# ATSAMC21N17A device description
Architecture: CORTEX-M0PLUS; Family: SAMC; Series: SAMC21
Registers are 32-bit, read-write, reset 0x0 unless marked. A register's access mark holds for its fields unless they carry their own. Offsets are from the block's base; [hi:lo] are bit positions; {n}, {i} and the like mark numbered series; 'fields as' and 'values as' point back to an identical list; <NAME> marks a mode.

## SERCOM — Serial Communication Interface
Instances: SERCOM{n} {0x42000400+0x400*n} (n=0..5), SERCOM6 0x43000000, SERCOM7 0x43000400
Modes: I2CM when SERCOM.I2CM_CTRLA.MODE=5 under mask 6 (I2C Master Mode); I2CS when SERCOM.I2CS_CTRLA.MODE=4 under mask 6 (I2C Slave Mode); SPIS when SERCOM.SPIS_CTRLA.MODE=2 under mask 6 (SPI Slave Mode); SPIM when SERCOM.SPIM_CTRLA.MODE=3 under mask 6 (SPI Master Mode); USART_EXT when SERCOM.USART_CTRLA.MODE=0 under mask 6 (USART EXTERNAL CLOCK Mode); USART_INT when SERCOM.USART_CTRLA.MODE=1 under mask 6 (USART INTERNAL CLOCK Mode)
0x00 CTRLA <I2CM> — I2CM Control A
  [30] LOWTOUTEN — SCL Low Timeout Enable
  [29:28] INACTOUT — Inactive Time-Out
    0=DISABLE (Disabled); 1=55US (5-6 SCL Time-Out(50-60us)); 2=105US (10-11 SCL Time-Out(100-110us)); 3=205US (20-21 SCL Time-Out(200-210us))
  [27] SCLSM — SCL Clock Stretch Mode
  [25:24] SPEED — Transfer Speed
    0=STANDARD_AND_FAST_MODE (Standard Mode(Sm) Upto 100kHz and Fast Mode(Fm) Upto 400kHz); 1=FASTPLUS_MODE (Fast-mode Plus Upto 1MHz); 2=HIGH_SPEED_MODE (High-speed mode Upto 3.4MHz)
  [23] SEXTTOEN — Slave SCL Low Extend Timeout
  [22] MEXTTOEN — Master SCL Low Extend Timeout
  [21:20] SDAHOLD — SDA Hold Time
    0=DISABLE (Disabled); 1=75NS (50-100ns hold time); 2=450NS (300-600ns hold time); 3=600NS (400-800ns hold time)
  [16] PINOUT — Pin Usage
  [7] RUNSTDBY — Run in Standby
  [4:2] MODE — Operating Mode
    0=USART_EXT_CLK (USART with external clock); 1=USART_INT_CLK (USART with internal clock); 2=SPI_SLAVE (SPI in slave operation); 3=SPI_MASTER (SPI in master operation); 4=I2C_SLAVE (I2C slave operation); 5=I2C_MASTER (I2C master operation)
  [1] ENABLE
  [0] SWRST — Software Reset
0x04 CTRLB <I2CM> — I2CM Control B
  [18] ACKACT — Acknowledge Action
  [17:16] CMD — Command
  [9] QCEN — Quick Command Enable
  [8] SMEN — Smart Mode Enable
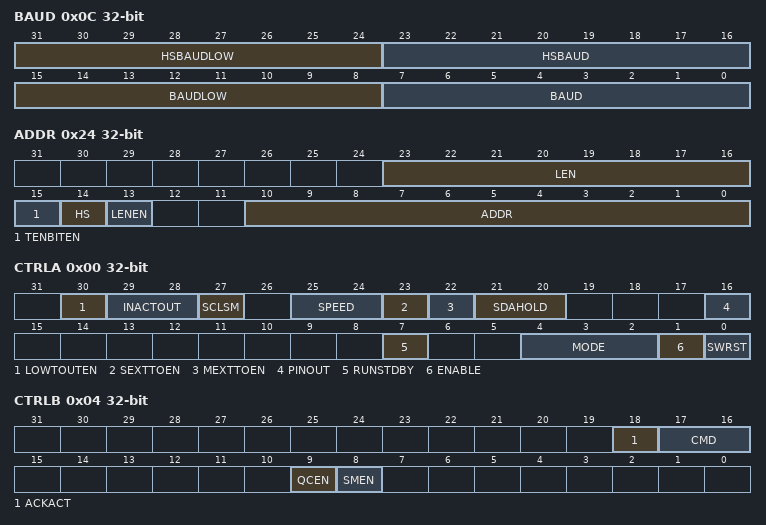
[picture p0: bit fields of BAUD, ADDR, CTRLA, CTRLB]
0x0C BAUD <I2CM> — I2CM Baud Rate
  [31:24] HSBAUDLOW — High Speed Baud Rate Value Low
  [23:16] HSBAUD — High Speed Baud Rate Value
  [15:8] BAUDLOW — Baud Rate Value Low
  [7:0] BAUD — Baud Rate Value
0x14 INTENCLR <I2CM> 8-bit (atomic clear) — I2CM Interrupt Enable Clear
  [7] ERROR — Combined Error Interrupt Disable
  [1] SB — Slave On Bus Interrupt Disable
  [0] MB — Master On Bus Interrupt Disable
0x16 INTENSET <I2CM> 8-bit (atomic set) — I2CM Interrupt Enable Set
  [7] ERROR — Combined Error Interrupt Enable
  [1] SB — Slave On Bus Interrupt Enable
  [0] MB — Master On Bus Interrupt Enable
0x18 INTFLAG <I2CM> 8-bit (atomic clear) — I2CM Interrupt Flag Status and Clear
  [7] ERROR — Combined Error Interrupt
  [1] SB — Slave On Bus Interrupt
  [0] MB — Master On Bus Interrupt
0x1A STATUS <I2CM> 16-bit — I2CM Status
  [10] LENERR — Length Error
  [9] SEXTTOUT — Slave SCL Low Extend Timeout
  [8] MEXTTOUT — Master SCL Low Extend Timeout
  [7] CLKHOLD — Clock Hold
  [6] LOWTOUT — SCL Low Timeout
  [5:4] BUSSTATE
  [2] RXNACK — Received Not Acknowledge
  [1] ARBLOST — Arbitration Lost
  [0] BUSERR — Bus Error
0x1C SYNCBUSY <I2CM> ro — I2CM Synchronization Busy
  [2] SYSOP — System Operation Synchronization Busy
  [1] ENABLE — SERCOM Enable Synchronization Busy
  [0] SWRST — Software Reset Synchronization Busy
0x24 ADDR <I2CM> — I2CM Address
  [23:16] LEN — Length
  [15] TENBITEN — Ten Bit Addressing Enable
  [14] HS — High Speed Mode
  [13] LENEN — Length Enable
  [10:0] ADDR — Address Value
0x28 DATA <I2CM> 8-bit — I2CM Data
  [7:0] DATA — Data Value
0x30 DBGCTRL <I2CM> 8-bit — I2CM Debug Control
  [0] DBGSTOP — Debug Mode
0x00 CTRLA <I2CS> — I2CS Control A
  [30] LOWTOUTEN — SCL Low Timeout Enable
  [27] SCLSM — SCL Clock Stretch Mode
  [25:24] SPEED — Transfer Speed
    values as CTRLA<I2CM>.SPEED
  [23] SEXTTOEN — Slave SCL Low Extend Timeout
  [21:20] SDAHOLD — SDA Hold Time
    values as CTRLA<I2CM>.SDAHOLD
  [16] PINOUT — Pin Usage
  [7] RUNSTDBY — Run during Standby
  [4:2] MODE — Operating Mode
    values as CTRLA<I2CM>.MODE
  [1] ENABLE
  [0] SWRST — Software Reset
0x04 CTRLB <I2CS> — I2CS Control B
  [18] ACKACT — Acknowledge Action
  [17:16] CMD — Command
  [15:14] AMODE — Address Mode
  [10] AACKEN — Automatic Address Acknowledge
  [9] GCMD — PMBus Group Command
  [8] SMEN — Smart Mode Enable
0x14 INTENCLR <I2CS> 8-bit (atomic clear) — I2CS Interrupt Enable Clear
  [7] ERROR — Combined Error Interrupt Disable
  [2] DRDY — Data Interrupt Disable
  [1] AMATCH — Address Match Interrupt Disable
  [0] PREC — Stop Received Interrupt Disable
0x16 INTENSET <I2CS> 8-bit (atomic set) — I2CS Interrupt Enable Set
  [7] ERROR — Combined Error Interrupt Enable
  [2] DRDY — Data Interrupt Enable
  [1] AMATCH — Address Match Interrupt Enable
  [0] PREC — Stop Received Interrupt Enable
0x18 INTFLAG <I2CS> 8-bit (atomic clear) — I2CS Interrupt Flag Status and Clear
  [7] ERROR — Combined Error Interrupt
  [2] DRDY — Data Interrupt
  [1] AMATCH — Address Match Interrupt
  [0] PREC — Stop Received Interrupt
0x1A STATUS <I2CS> 16-bit — I2CS Status
  [10] HS — High Speed
  [9] SEXTTOUT — Slave SCL Low Extend Timeout
  [7] CLKHOLD — Clock Hold
  [6] LOWTOUT — SCL Low Timeout
  [4] SR — Repeated Start
  [3] DIR — Read/Write Direction
  [2] RXNACK — Received Not Acknowledge
  [1] COLL — Transmit Collision
  [0] BUSERR — Bus Error
0x1C SYNCBUSY <I2CS> ro — I2CS Synchronization Busy
  [1] ENABLE — SERCOM Enable Synchronization Busy
  [0] SWRST — Software Reset Synchronization Busy
0x24 ADDR <I2CS> — I2CS Address
  [26:17] ADDRMASK — Address Mask
  [15] TENBITEN — Ten Bit Addressing Enable
  [10:1] ADDR — Address Value
  [0] GENCEN — General Call Address Enable
0x28 DATA <I2CS> 8-bit — I2CS Data
  [7:0] DATA — Data Value
0x00 CTRLA <SPIM> — SPIM Control A
  [30] DORD — Data Order
    0=MSB (MSB is transferred first); 1=LSB (LSB is transferred first)
  [29] CPOL — Clock Polarity
    0=IDLE_LOW (SCK is low when idle); 1=IDLE_HIGH (SCK is high when idle)
  [28] CPHA — Clock Phase
    0=LEADING_EDGE (The data is sampled on a leading SCK edge and changed on a trailing SCK edge); 1=TRAILING_EDGE (The data is sampled on a trailing SCK edge and changed on a leading SCK edge)
  [27:24] FORM — Frame Format
    0=SPI_FRAME; 2=SPI_FRAME_WITH_ADDR
  [21:20] DIPO — Data In Pinout
    {v}=PAD{v} (SERCOM PAD[{v}]) (v=0..3)
  [17:16] DOPO — Data Out Pinout
    0=PAD0 (DO on PAD[0], SCK on PAD[1] and SS on PAD[2]); 1=PAD1 (DO on PAD[2], SCK on PAD[3] and SS on PAD[1]); 2=PAD2 (DO on PAD[3], SCK on PAD[1] and SS on PAD[2]); 3=PAD3 (DO on PAD[0], SCK on PAD[3] and SS on PAD[1])
  [8] IBON — Immediate Buffer Overflow Notification
  [7] RUNSTDBY — Run during Standby
  [4:2] MODE — Operating Mode
    values as CTRLA<I2CM>.MODE
  [1] ENABLE
  [0] SWRST — Software Reset
0x04 CTRLB <SPIM> (WSYNC) — SPIM Control B
  [17] RXEN — Receiver Enable
  [15:14] AMODE — Address Mode
    0=MASK (SPI Address mask); 1=2_ADDRESSES (Two unique Addressess); 2=RANGE (Address Range)
  [13] MSSEN — Master Slave Select Enable
  [9] SSDE — Slave Select Low Detect Enable
  [6] PLOADEN — Data Preload Enable
  [2:0] CHSIZE — Character Size
    0=8_BIT (8 bits); 1=9_BIT (9 bits)
0x0C BAUD <SPIM> 8-bit — SPIM Baud Rate
  [7:0] BAUD — Baud Rate Value
0x14 INTENCLR <SPIM> 8-bit (atomic clear) — SPIM Interrupt Enable Clear
  [7] ERROR — Combined Error Interrupt Disable
  [3] SSL — Slave Select Low Interrupt Disable
  [2] RXC — Receive Complete Interrupt Disable
  [1] TXC — Transmit Complete Interrupt Disable
  [0] DRE — Data Register Empty Interrupt Disable
0x16 INTENSET <SPIM> 8-bit (atomic set) — SPIM Interrupt Enable Set
  [7] ERROR — Combined Error Interrupt Enable
  [3] SSL — Slave Select Low Interrupt Enable
  [2] RXC — Receive Complete Interrupt Enable
  [1] TXC — Transmit Complete Interrupt Enable
  [0] DRE — Data Register Empty Interrupt Enable
0x18 INTFLAG <SPIM> 8-bit (atomic clear) — SPIM Interrupt Flag Status and Clear
  [7] ERROR — Combined Error Interrupt
  [3] SSL — Slave Select Low Interrupt Flag
  [2] RXC — Receive Complete Interrupt
  [1] TXC — Transmit Complete Interrupt
  [0] DRE — Data Register Empty Interrupt
0x1A STATUS <SPIM> 16-bit — SPIM Status
  [2] BUFOVF — Buffer Overflow
0x1C SYNCBUSY <SPIM> ro — SPIM Synchronization Busy
  [2] CTRLB — CTRLB Synchronization Busy
  [1] ENABLE — SERCOM Enable Synchronization Busy
  [0] SWRST — Software Reset Synchronization Busy
0x24 ADDR <SPIM> — SPIM Address
  [23:16] ADDRMASK — Address Mask
  [7:0] ADDR — Address Value
0x28 DATA <SPIM> — SPIM Data
  [8:0] DATA — Data Value
0x30 DBGCTRL <SPIM> 8-bit — SPIM Debug Control
  [0] DBGSTOP — Debug Mode
0x00 CTRLA <SPIS> — SPIS Control A
  fields as CTRLA<SPIM>
0x04 CTRLB <SPIS> (WSYNC) — SPIS Control B
  fields as CTRLB<SPIM>
0x0C BAUD <SPIS> 8-bit — SPIS Baud Rate
  [7:0] BAUD — Baud Rate Value
0x14 INTENCLR <SPIS> 8-bit (atomic clear) — SPIS Interrupt Enable Clear
  fields as INTENCLR<SPIM>
0x16 INTENSET <SPIS> 8-bit (atomic set) — SPIS Interrupt Enable Set
  fields as INTENSET<SPIM>
0x18 INTFLAG <SPIS> 8-bit (atomic clear) — SPIS Interrupt Flag Status and Clear
  fields as INTFLAG<SPIM>
0x1A STATUS <SPIS> 16-bit — SPIS Status
  [2] BUFOVF — Buffer Overflow
0x1C SYNCBUSY <SPIS> ro — SPIS Synchronization Busy
  fields as SYNCBUSY<SPIM>
0x24 ADDR <SPIS> — SPIS Address
  [23:16] ADDRMASK — Address Mask
  [7:0] ADDR — Address Value
0x28 DATA <SPIS> — SPIS Data
  [8:0] DATA — Data Value
0x30 DBGCTRL <SPIS> 8-bit — SPIS Debug Control
  [0] DBGSTOP — Debug Mode
0x00 CTRLA <USART_EXT> — USART_EXT Control A
  [30] DORD — Data Order
    0=MSB (MSB is transmitted first); 1=LSB (LSB is transmitted first)
  [29] CPOL — Clock Polarity
    0=IDLE_LOW (TxD Change:- Rising XCK edge, RxD Sample:- Falling XCK edge); 1=IDLE_HIGH (TxD Change:- Falling XCK edge, RxD Sample:- Rising XCK edge)
  [28] CMODE — Communication Mode
    0=ASYNC (Asynchronous Communication); 1=SYNC (Synchronous Communication)
  [27:24] FORM — Frame Format
    0=USART_FRAME_NO_PARITY; 1=USART_FRAME_WITH_PARITY; 2=USART_FRAME_LIN_MASTER_MODE (LIN Master - Break and sync generation); 4=USART_FRAME_AUTO_BAUD_NO_PARITY (Auto-baud (LIN Slave) - break detection and auto-baud); 5=USART_FRAME_AUTO_BAUD_WITH_PARITY (Auto-baud - break detection and auto-baud with parity)
  [23:22] SAMPA — Sample Adjustment
    0=ADJ0 (16x Over-sampling = 7-8-9; 8x Over-sampling = 3-4-5); 1=ADJ1 (16x Over-sampling = 9-10-11; 8x Over-sampling = 4-5-6); 2=ADJ2 (16x Over-sampling = 11-12-13; 8x Over-sampling = 5-6-7); 3=ADJ3 (16x Over-sampling = 13-14-15; 8x Over-sampling = 6-7-8)
  [21:20] RXPO — Receive Data Pinout
    {v}=PAD{v} (SERCOM PAD[{v}] is used for data reception) (v=0..3)
  [17:16] TXPO — Transmit Data Pinout
    0=PAD0 (PAD[0] = TxD; PAD[1] = XCK); 1=PAD1 (PAD[2] = TxD; PAD[3] = XCK); 2=PAD2 (PAD[0] = TxD; PAD[2] = RTS; PAD[3] = CTS); 3=PAD3 (PAD[0] = TxD; PAD[1] = XCK; PAD[2] = TE)
  [15:13] SAMPR — Sample
    0=16X_ARITHMETIC (16x over-sampling using arithmetic baudrate generation); 1=16X_FRACTIONAL (16x over-sampling using fractional baudrate generation); 2=8X_ARITHMETIC (8x over-sampling using arithmetic baudrate generation); 3=8X_FRACTIONAL (8x over-sampling using fractional baudrate generation); 4=3X_ARITHMETIC (3x over-sampling using arithmetic baudrate generation)
  [8] IBON — Immediate Buffer Overflow Notification
  [7] RUNSTDBY — Run during Standby
  [4:2] MODE — Operating Mode
    values as CTRLA<I2CM>.MODE
  [1] ENABLE
  [0] SWRST — Software Reset
0x04 CTRLB <USART_EXT> (WSYNC) — USART_EXT Control B
  [25:24] LINCMD — LIN Command
    0=NONE (Normal USART transmission); 1=SOFTWARE_CONTROL_TRANSMIT_CMD (Break field is transmitted when DATA is written); 2=AUTO_TRANSMIT_CMD (Break, sync and identifier are automatically transmitted when DATA is written with the identifier)
  [17] RXEN — Receiver Enable
  [16] TXEN — Transmitter Enable
  [13] PMODE — Parity Mode
    0=EVEN (Even Parity); 1=ODD (Odd Parity)
  [10] ENC — Encoding Format
  [9] SFDE — Start of Frame Detection Enable
  [8] COLDEN — Collision Detection Enable
  [6] SBMODE — Stop Bit Mode
    0=1_BIT (One Stop Bit); 1=2_BIT (Two Stop Bits)
  [2:0] CHSIZE — Character Size
    0=8_BIT (8 Bits); 1=9_BIT (9 Bits); 5=5_BIT (5 Bits); 6=6_BIT (6 Bits); 7=7_BIT (7 Bits)
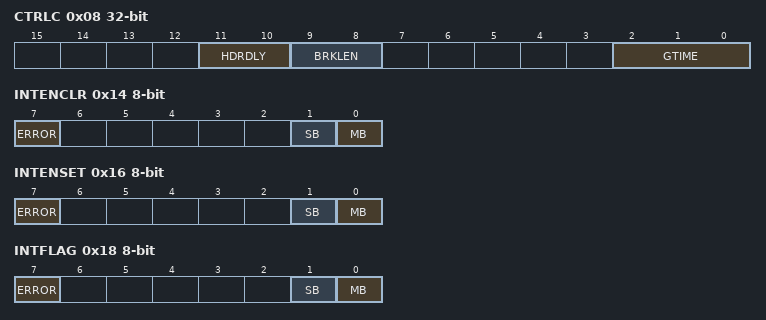
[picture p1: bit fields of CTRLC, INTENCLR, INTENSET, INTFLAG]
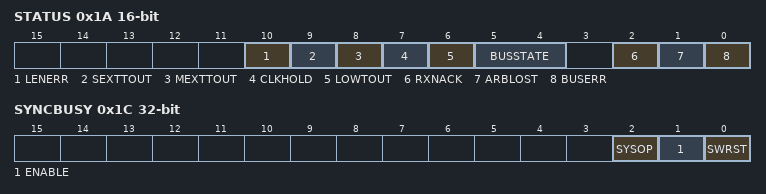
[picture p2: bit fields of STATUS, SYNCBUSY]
0x08 CTRLC <USART_EXT> — USART_EXT Control C
  [11:10] HDRDLY — LIN Master Header Delay
    0=DELAY0 (Delay between break and sync transmission is 1 bit time; Delay between sync and ID transmission is 1 bit time); 1=DELAY1 (Delay between break and sync transmission is 4 bit time; Delay between sync and ID transmission is 4 bit time); 2=DELAY2 (Delay between break and sync transmission is 8 bit time; Delay between sync and ID transmission is 4 bit time); 3=DELAY3 (Delay between break and sync transmission is 14 bit time; Delay between sync and ID transmission is 4 bit time)
  [9:8] BRKLEN — LIN Master Break Length
    0=13_BIT (Break field transmission is 13 bit times); 1=17_BIT (Break field transmission is 17 bit times); 2=21_BIT (Break field transmission is 21 bit times); 3=26_BIT (Break field transmission is 26 bit times)
  [2:0] GTIME — RS485 Guard Time
0x0C BAUD <USART_EXT> 16-bit — USART_EXT Baud Rate
  [15:0] BAUD <DEFAULT USARTFP> — Baud Rate Value
  [15:13] FP <FRAC FRACFP> — Fractional Part
  [12:0] BAUD <FRAC FRACFP> — Baud Rate Value
0x0E RXPL <USART_EXT> 8-bit — USART_EXT Receive Pulse Length
  [7:0] RXPL — Receive Pulse Length
0x14 INTENCLR <USART_EXT> 8-bit (atomic clear) — USART_EXT Interrupt Enable Clear
  [7] ERROR — Combined Error Interrupt Disable
  [5] RXBRK — Break Received Interrupt Disable
  [4] CTSIC — Clear To Send Input Change Interrupt Disable
  [3] RXS — Receive Start Interrupt Disable
  [2] RXC — Receive Complete Interrupt Disable
  [1] TXC — Transmit Complete Interrupt Disable
  [0] DRE — Data Register Empty Interrupt Disable
0x16 INTENSET <USART_EXT> 8-bit (atomic set) — USART_EXT Interrupt Enable Set
  [7] ERROR — Combined Error Interrupt Enable
  [5] RXBRK — Break Received Interrupt Enable
  [4] CTSIC — Clear To Send Input Change Interrupt Enable
  [3] RXS — Receive Start Interrupt Enable
  [2] RXC — Receive Complete Interrupt Enable
  [1] TXC — Transmit Complete Interrupt Enable
  [0] DRE — Data Register Empty Interrupt Enable
0x18 INTFLAG <USART_EXT> 8-bit (atomic clear) — USART_EXT Interrupt Flag Status and Clear
  [7] ERROR — Combined Error Interrupt
  [5] RXBRK — Break Received Interrupt
  [4] CTSIC — Clear To Send Input Change Interrupt
  [3] RXS — Receive Start Interrupt
  [2] RXC — Receive Complete Interrupt
  [1] TXC — Transmit Complete Interrupt
  [0] DRE — Data Register Empty Interrupt
0x1A STATUS <USART_EXT> 16-bit — USART_EXT Status
  [6] TXE — Transmitter Empty
  [5] COLL — Collision Detected
  [4] ISF — Inconsistent Sync Field
  [3] CTS — Clear To Send
  [2] BUFOVF — Buffer Overflow
  [1] FERR — Frame Error
  [0] PERR — Parity Error
0x1C SYNCBUSY <USART_EXT> ro — USART_EXT Synchronization Busy
  fields as SYNCBUSY<SPIM>
0x28 DATA <USART_EXT> 16-bit — USART_EXT Data
  [8:0] DATA — Data Value
0x30 DBGCTRL <USART_EXT> 8-bit — USART_EXT Debug Control
  [0] DBGSTOP — Debug Mode
0x00 CTRLA <USART_INT> — USART_INT Control A
  fields as CTRLA<USART_EXT>
0x04 CTRLB <USART_INT> (WSYNC) — USART_INT Control B
  fields as CTRLB<USART_EXT>
0x08 CTRLC <USART_INT> — USART_INT Control C
  fields as CTRLC<USART_EXT>
0x0C BAUD <USART_INT> 16-bit — USART_INT Baud Rate
  fields as BAUD<USART_EXT>
0x0E RXPL <USART_INT> 8-bit — USART_INT Receive Pulse Length
  [7:0] RXPL — Receive Pulse Length
0x14 INTENCLR <USART_INT> 8-bit (atomic clear) — USART_INT Interrupt Enable Clear
  fields as INTENCLR<USART_EXT>
0x16 INTENSET <USART_INT> 8-bit (atomic set) — USART_INT Interrupt Enable Set
  fields as INTENSET<USART_EXT>
0x18 INTFLAG <USART_INT> 8-bit (atomic clear) — USART_INT Interrupt Flag Status and Clear
  fields as INTFLAG<USART_EXT>
0x1A STATUS <USART_INT> 16-bit — USART_INT Status
  fields as STATUS<USART_EXT>
0x1C SYNCBUSY <USART_INT> ro — USART_INT Synchronization Busy
  fields as SYNCBUSY<SPIM>
0x28 DATA <USART_INT> 16-bit — USART_INT Data
  [8:0] DATA — Data Value
0x30 DBGCTRL <USART_INT> 8-bit — USART_INT Debug Control
  [0] DBGSTOP — Debug Mode

## Notices in the file
Copyright (c) 2018 Microchip Technology Inc.
SPDX-License-Identifier: Apache-2.0
Licensed under the Apache License, Version 2.0 (the "License");
you may not use this file except in compliance with the License.
You may obtain a copy of the License at
http://www.apache.org/licenses/LICENSE-2.0
Unless required by applicable law or agreed to in writing, software
distributed under the License is distributed on an "AS IS" BASIS,
WITHOUT WARRANTIES OR CONDITIONS OF ANY KIND, either express or implied.
See the License for the specific language governing permissions and
limitations under the License.
